# TLE9273 register map
Vendor: Infineon; File version: 0.1
TLE9273 Family
Registers are 8-bit, read-write, no defined reset value unless marked. A register's access mark holds for its fields unless they carry their own. Offsets are from the block's base; lines under a group give offsets from that group; [hi:lo] are bit positions; {n}, {i} and the like mark numbered series; 'fields as' and 'values as' point back to an identical list; <NAME> marks a mode.

## Memory map
0x00000000 CTRL size 0x40 — Control
0x00000040 STAT size 0x40 — Status

## STAT — Status
Base 0x00000040
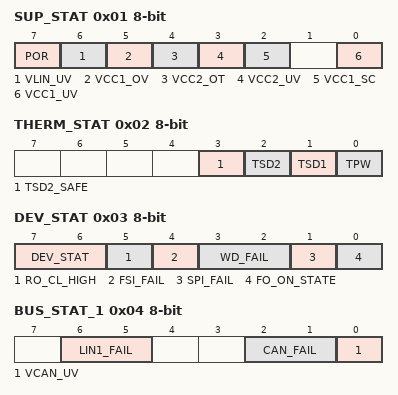
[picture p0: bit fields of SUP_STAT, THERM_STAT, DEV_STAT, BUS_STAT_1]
0x01 SUP_STAT ro — Supply Voltage Fail Status
  [7] POR — Power-On Reset Detection
    0=not_detected (No POR); 1=detected (POR occurred)
  [6] VLIN_UV — VLIN Under-Voltage Detection
    0=not_detected (No VLIN_UV); 1=detected (VLIN_UV detected)
  [5] VCC1_OV — Vcc1 Over-Voltage Detection
    0=not_detected (No VCC1 OV); 1=detected (VCC1 OV detected)
  [4] VCC2_OT — VCC2 Over Temperature Detection
    0=not_detected (No over temperature); 1=detected (VCC2 over temperature detected)
  [3] VCC2_UV — VCC2 Under Voltage Detection ()
    0=not_detected (No VCC2 Under voltage); 1=detected (VCC2 under voltage detected)
  [2] VCC1_SC — VCC1 Short to GND Detection (<Vrtx for t>2ms after switch on)
    0=not_detected (No short); 1=detected (VCC1 short to GND detected)
  [0] VCC1_UV — VCC1 UV-Detection (due to Vrtx reset)
    0=not_detected (No VCC1_UV detection); 1=detected (VCC1 UV-Fail detected)
0x02 THERM_STAT ro — Thermal Protection Status
  [3] TSD2_SAFE — TSD2 Thermal Shut-Down Safe State Detection
    0=not_detected (No TSD2 safe state detected); 1=detected (TSD2 safe state detected: >16 consecutive TSD2 events occurred, next TSD2 waiting time will be 60s)
  [2] TSD2 — TSD2 Thermal Shut-Down Detection
    0=not_detected (No TSD2 event); 1=detected (TSD2 OT detected - leading to SBC Fail-Safe Mode)
  [1] TSD1 — TSD1 Thermal Shut-Down Detection
    0=not_detected (No TSD1 fail); 1=detected (TSD1 OT detected (affected module is disabled))
  [0] TPW — Thermal Pre Warning
    0=not_detected (No Thermal Pre warning); 1=detected (Thermal Pre warning detected)
0x03 DEV_STAT ro — Device Information Status
  [7:6] DEV_STAT — Device Status before Restart Mode
    0=Cleared (Register must be actively cleared); 1=failure (Restart due to failure (WD fail, TSD2, VCC1_UV, trial to access SLEEP MODE without any wake source activated); also after a wake from Fail-Safe Mode); 2=Sleep_Mode
  [5] RO_CL_HIGH — Reset PIN Clamped to HIGH level detected
    0=not_detected (No Reset Clamped to HIGH detected); 1=detected (Reset Clamped to HIGH detected)
  [4] FSI_FAIL — FSI Fail information
    0=not_detected (No FSI fail); 1=detected (Failure on FSI pattern recognized)
  [3:2] WD_FAIL — Number of WD-Failure Events (1/2 WD failures depending on CFG1)
    0=not_detected (No WD Fail); 1=1x WD Fail, FO activation - Config 2 selected; 2=2x WD Fail, FO activation - Config 1 / 3 / 4 selected
  [1] SPI_FAIL — SPI Fail Information
    0=not_detected (No SPI fail); 1=detected (Invalid SPI command detected)
  [0] FO_ON_STATE — Activation of Fail Output FO
    0=not_detected (No Failure); 1=detected (Failure occurred)
0x04 BUS_STAT_1 ro — Bus Communication Status
  [6:5] LIN1_FAIL — LIN1 Failure Status
    0=No error; 1=LIN1 TSD; 2=LIN1_TXD_DOM (TXD dominant time out for more than 20ms); 3=LIN1_BUS_DOM (BUS dominant time out for more than 20ms)
  [2:1] CAN_FAIL — CAN Failure Status
    0=none (No error); 1=TSD_shutdown (CAN TSD shutdown); 2=TXD_DOM (CAN_TXD_DOM: TXD dominant time out detected ()); 3=BUS_DOM (11) (CAN_BUS_DOM: BUS dominant time out detected ())
  [0] VCAN_UV — Undervoltage CAN Bus Supply
    0=detected (Normal operation); 1=not_detected (CAN Supply undervoltage detected. Transmitter disabled)
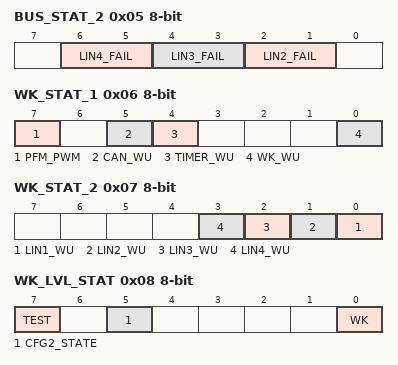
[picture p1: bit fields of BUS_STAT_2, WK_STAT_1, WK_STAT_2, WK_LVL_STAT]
0x05 BUS_STAT_2 ro — Bus Communication Status
  [6:5] LIN4_FAIL — LIN Failure Status
    0=No_error; 1=LIN4_TSD_shutdown (LIN TSD shutdown, also TSD1 signaled); 2=LIN4_TXD_DOM (LIN_TXD_DOM: TXDLIN dominant time out); 3=LIN4_BUS_DOM (LIN_BUS_DOM: BUS dominant time out)
  [4:3] LIN3_FAIL — LIN Failure Status
    0=No_error; 1=LIN3_TSD_shutdown (LIN TSD shutdown, also TSD1 signaled); 2=LIN3_TXD_DOM (LIN_TXD_DOM: TXDLIN dominant time out); 3=LIN3_BUS_DOM (LIN_BUS_DOM: BUS dominant time out)
  [2:1] LIN2_FAIL — LIN2 Failure Status
    0=No_error; 1=LIN2_TSD_shutdown (LIN TSD shutdown, also TSD1 signaled); 2=LIN2_TXD_DOM (LIN_TXD_DOM: TXDLIN dominant time out); 3=LIN2_BUS_DOM (LIN_BUS_DOM: BUS dominant time out)
0x06 WK_STAT_1 ro — Wake-up Source and Information Status
  [7] PFM_PWM — PFM_PWM automatic transition detected
    0=not_detected (No automatic PFM_PWM transition detected); 1=detected (Automatic PFM_PWM transition detected)
  [5] CAN_WU — Wake up via CAN Bus
    0=not_detected (No Wake up); 1=detected (Wake up)
  [4] TIMER_WU — Wake up via TimerX
    0=not_detected (No Wake up); 1=detected (Wake up)
  [0] WK_WU — Wake up via WK
    0=not_detected (No Wake up); 1=detected (Wake up)
0x07 WK_STAT_2 ro — Wake-up Source and Information Status
  [all] fields
    0=not_detected (No Wake up); 1=detected (Wake up)
  [n-1] LIN{n}_WU (n=1..4) — Wake up via LIN{n} Bus
0x08 WK_LVL_STAT ro — WK Input Level
  [7] TEST — Status of TEST Pin
    0=LOW Level (=0); 1=HIGH Level (=1), SBC Software Development Mode is enabled, No reset triggered due to wrong watchdog trigger
  [5] CFG2_STATE — Status of CFG2 bit on HW_CTRL register
    0=LOW Level; Fail Outputs (FOx) are active after 2nd watchdog trigger fail Config 3; 1=HIGH Level; Fail Outputs (FOx) are active after 1st watchdog trigger fail Config 1
  [0] WK — Status of WK
    0=Low Level (=0); 1=High Level (=1)
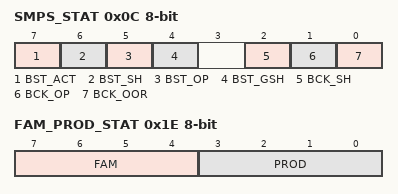
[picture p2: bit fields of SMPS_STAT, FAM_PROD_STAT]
0x0C SMPS_STAT ro — SMPS state
  [7] BST_ACT — Boost Regulator Active
    0=not_active (Boost not active); 1=active (Boost active)
  [6] BST_SH — BSTD and SNSP short detection
    0=not_detected (No short detected on BSTD and SNSP pins); 1=detected (BSTD or SNSP pins short to GND)
  [5] BST_OP — BSTD, SNSP SNSN open detection
    0=not_detected (No open detection in BSTD, SNSP and SNSN pins); 1=detected (Or operation between: BSTD loss of diode detected, SNSP loss of resistor detected, SNSN loss of GND detected)
  [4] BST_GSH — BSTG pin short detection
    0=not_detected (BSTG no short detected); 1=detected (BSTG short detected to GND or internal supply)
  [2] BCK_SH — BCKSW pin short detection
    0=not_detected (No short detected); 1=detected (Short to GND or short to VS detected on BCKSW pin)
  [1] BCK_OP — BCKSW pin open detection
    0=not_detected (No BCKSW open detected); 1=detected (BCKSW open detected)
  [0] BCK_OOR — VCC1 Out of Range
    0=inside (VCC1 inside VCC1,out1±12%); 1=outside (VCC1 outside VCC1,out1±12%)
0x1E FAM_PROD_STAT ro — Family and Product Identification Register
  [7:4] FAM — SBC Family Identifier (bit4=LSB; bit7=MSB)
    1=HERA (Driver SBC Family (HERA)); 2=HERCULES (DC/DC-SBC Family (HERCULES)); 3=ATHENA (Mid-Range SBC Family (ATHENA)); 4=MCP (Multi-CAN SBC Family (MCP)); 5=LITE (LITE SBC Family (LITE)); 7=ATHENA+ (Mid-Range+ SBC Family (ATHENA+))
  [3:0] PROD — SBC Product Identifier (bit0=LSB; bit3=MSB)
    4=TLE9461ES (TLE9461ES (VCC1 = 5V, no SWK)); 5=TLE9461ESV33 (TLE9461ESV33 (VCC1 = 3.3V, no SWK)); 6=TLE9461-3ES (TLE9461-3ES (VCC1 = 5V, SWK) (default value if device is not fused)); 7=TLE9461-3ESV33 (TLE9461-3ESV33 (VCC1 = 3.3V, SWK)); 12=TLE9471ES (TLE9471ES (VCC1 = 5V, no SWK)); 13=TLE9471ESV33 (TLE9471ESV33 (VCC1 = 3.3V, no SWK)); 14=TLE9471-3ES (TLE9471-3ES(VCC1 = 5V, SWK)); 15=TLE9471-3ESV33 (TLE9471-3ESV33 (VCC1 = 3.3V, SWK))
